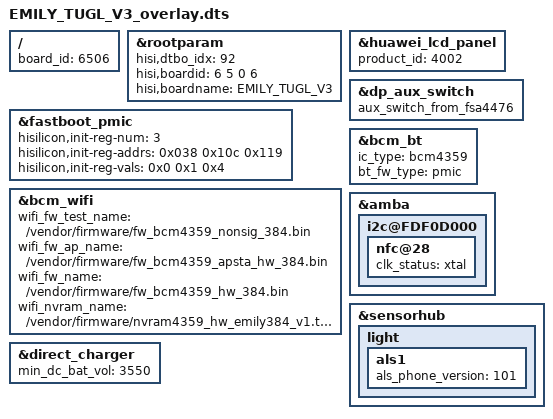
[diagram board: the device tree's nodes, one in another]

/**
 * Copyright (C) 2014 Hisilicon Ltd.
 *
 *  This program is free software; you can redistribute it and/or modify
 *  it under the terms of the GNU General Public License version 2 as
 *  publishhed by the Free Software Foundation.
 */

/dts-v1/;
/plugin/;
/include/ "EMILY_TUGL_V1_overlay.dtsi"
/include/ "EMILY_TUGL_V3_overlay_module_amba.dts"

/ {
        board_id = <6506>;
};

&rootparam {
        hisi,dtbo_idx = <92>;
    hisi,boardid = <6 5 0 6>;
    hisi,boardname = "EMILY_TUGL_V3";
};


&fastboot_pmic {
       hisilicon,init-reg-num = <3>;
       hisilicon,init-reg-addrs = <0x038 0x10c 0x119>;
       hisilicon,init-reg-vals  = <0x0 0x1 0x4>;
};

&huawei_lcd_panel {
       product_id = <4002>;
};

&dp_aux_switch {
    aux_switch_from_fsa4476;
    status = "ok";
};

&bcm_wifi {
	wifi_fw_test_name = "/vendor/firmware/fw_bcm4359_nonsig_384.bin";
	wifi_fw_ap_name = "/vendor/firmware/fw_bcm4359_apsta_hw_384.bin";
	wifi_fw_name = "/vendor/firmware/fw_bcm4359_hw_384.bin";
	wifi_nvram_name = "/vendor/firmware/nvram4359_hw_emily384_v1.txt";
};

&bcm_bt {
	ic_type = "bcm4359";
	bt_fw_type = "pmic";
	status = "ok";
};

&amba {
    i2c@FDF0D000 {
        nfc@28 {
            clk_status ="xtal";
        };
    };
};

&sensorhub{
                light{
                        als1{
                               als_phone_version = <101>;
                        };
                };
        };
&direct_charger {
	min_dc_bat_vol = <3550>;
};
